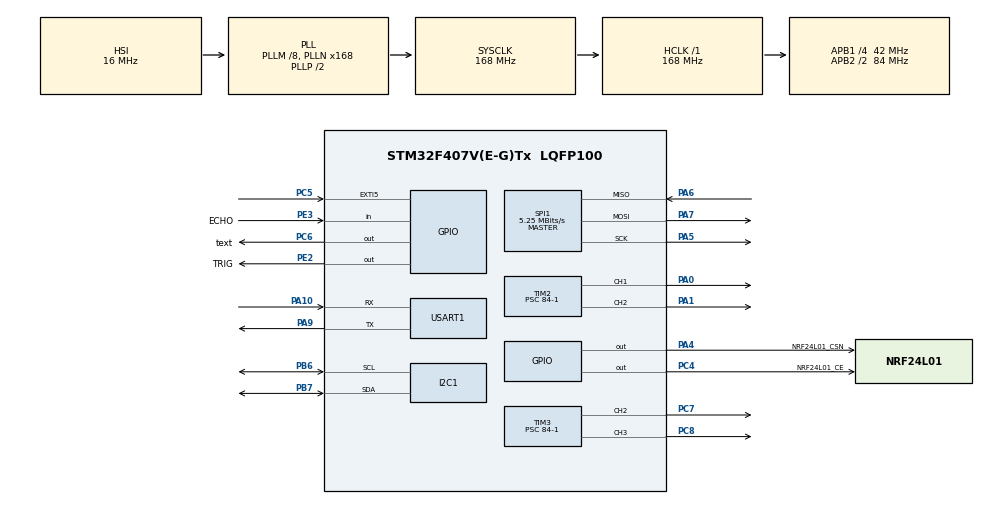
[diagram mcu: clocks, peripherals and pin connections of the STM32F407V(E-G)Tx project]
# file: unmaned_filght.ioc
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FREERTOS.Tasks01=defaultTask,24,128,StartDefaultTask,Default,NULL,Dynamic,NULL,NULL
I2C1.I2C_Mode=I2C_Fast
Mcu.Family=STM32F4
Mcu.Name=STM32F407V(E-G)Tx
Mcu.Package=LQFP100
NVIC.PriorityGroup=NVIC_PRIORITYGROUP_4
NVIC.TIM8_TRG_COM_TIM14_IRQn=true\:15\:0\:false\:false\:true\:false\:false\:true\:true
NVIC.TimeBase=TIM8_TRG_COM_TIM14_IRQn
NVIC.TimeBaseIP=TIM14
PA0-WKUP.Signal=S_TIM2_CH1_ETR
PA1.Signal=S_TIM2_CH2
PA10.Mode=Asynchronous
PA10.Signal=USART1_RX
PA13.Mode=Serial_Wire
PA13.Signal=SYS_JTMS-SWDIO
PA14.Mode=Serial_Wire
PA14.Signal=SYS_JTCK-SWCLK
PA4.GPIO_Label=NRF24L01_CSN
PA4.PinState=GPIO_PIN_SET
PA4.Signal=GPIO_Output
PA5.Mode=Full_Duplex_Master
PA5.Signal=SPI1_SCK
PA6.GPIO_PuPd=GPIO_PULLUP
PA6.Mode=Full_Duplex_Master
PA6.Signal=SPI1_MISO
PA7.Mode=Full_Duplex_Master
PA7.Signal=SPI1_MOSI
PA9.Mode=Asynchronous
PA9.Signal=USART1_TX
PB6.Mode=I2C
PB6.Signal=I2C1_SCL
PB7.Mode=I2C
PB7.Signal=I2C1_SDA
PC4.GPIO_Label=NRF24L01_CE
PC4.Signal=GPIO_Output
PC5.Signal=GPXTI5
PC6.GPIO_Label=text
PC6.Signal=GPIO_Output
PC7.Signal=S_TIM3_CH2
PC8.Signal=S_TIM3_CH3
PE2.GPIO_Label=TRIG
PE2.Signal=GPIO_Output
PE3.GPIO_Label=ECHO
PE3.Signal=GPIO_Input
PH0-OSC_IN.Mode=HSE-External-Oscillator
PH0-OSC_IN.Signal=RCC_OSC_IN
PH1-OSC_OUT.Mode=HSE-External-Oscillator
PH1-OSC_OUT.Signal=RCC_OSC_OUT
ProjectManager.HeapSize=0x200
ProjectManager.StackSize=0x400
ProjectManager.TargetToolchain=CMake
RCC.48MHZClocksFreq_Value=84000000
RCC.AHBFreq_Value=168000000
RCC.APB1CLKDivider=RCC_HCLK_DIV4
RCC.APB1Freq_Value=42000000
RCC.APB1TimFreq_Value=84000000
RCC.APB2CLKDivider=RCC_HCLK_DIV2
RCC.APB2Freq_Value=84000000
RCC.APB2TimFreq_Value=168000000
RCC.CortexFreq_Value=168000000
RCC.HCLKFreq_Value=168000000
RCC.HSE_VALUE=25000000
RCC.HSI_VALUE=16000000
RCC.LSE_VALUE=32768
RCC.PLLM=8
RCC.PLLN=168
RCC.SYSCLKFreq_VALUE=168000000
RCC.SYSCLKSource=RCC_SYSCLKSOURCE_PLLCLK
RCC.VCOOutputFreq_Value=336000000
SH.S_TIM2_CH1_ETR.0=TIM2_CH1,PWM Generation1 CH1
SH.S_TIM2_CH2.0=TIM2_CH2,PWM Generation2 CH2
SH.S_TIM3_CH2.0=TIM3_CH2,PWM Generation2 CH2
SH.S_TIM3_CH3.0=TIM3_CH3,PWM Generation3 CH3
SPI1.BaudRatePrescaler=SPI_BAUDRATEPRESCALER_16
SPI1.CalculateBaudRate=5.25 MBits/s
SPI1.Direction=SPI_DIRECTION_2LINES
SPI1.Mode=SPI_MODE_MASTER
SPI1.VirtualType=VM_MASTER
TIM2.Channel-PWM\ Generation1\ CH1=TIM_CHANNEL_1
TIM2.Channel-PWM\ Generation2\ CH2=TIM_CHANNEL_2
TIM2.Period=20000-1
TIM2.Prescaler=84-1
TIM2.Pulse-PWM\ Generation1\ CH1=1000
TIM2.Pulse-PWM\ Generation2\ CH2=1000
TIM3.Channel-PWM\ Generation2\ CH2=TIM_CHANNEL_2
TIM3.Channel-PWM\ Generation3\ CH3=TIM_CHANNEL_3
TIM3.Period=20000-1
TIM3.Prescaler=84-1
TIM3.Pulse-PWM\ Generation3\ CH3=1000
TIM4.Prescaler=84-1
USART1.VirtualMode=VM_ASYNC
VP_FREERTOS_VS_CMSIS_V2.Mode=CMSIS_V2
VP_SYS_VS_tim14.Mode=TIM14
VP_TIM2_VS_ClockSourceINT.Mode=Internal
VP_TIM3_VS_ClockSourceINT.Mode=Internal
VP_TIM4_VS_ClockSourceINT.Mode=Internal
board=custom

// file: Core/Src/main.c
/* USER CODE BEGIN Header */
/**
 ******************************************************************************
 * @file           : main.c
 * @brief          : Main program body
 ******************************************************************************
 * @attention
 *
 * Copyright (c) 2026 STMicroelectronics.
 * All rights reserved.
 *
 * This software is licensed under terms that can be found in the LICENSE file
 * in the root directory of this software component.
 * If no LICENSE file comes with this software, it is provided AS-IS.
 *
 ******************************************************************************
 */
/* USER CODE END Header */
#include "main.h"
#include "cmsis_os.h"
#include "i2c.h"
#include "spi.h"
#include "tim.h"
#include "usart.h"
#include "gpio.h"

/* USER CODE BEGIN Includes */
#include "freertos_start.h"
/* USER CODE END Includes */

void SystemClock_Config(void);
void MX_FREERTOS_Init(void);

int main(void)
{

  /* MCU Configuration--------------------------------------------------------*/

  /* Reset of all peripherals, Initializes the Flash interface and the Systick. */
  HAL_Init();

  /* Configure the system clock */
  SystemClock_Config();

  /* Initialize all configured peripherals */
  MX_GPIO_Init();
  MX_SPI1_Init();
  MX_USART1_UART_Init();
  MX_I2C1_Init();
  MX_TIM2_Init();
  MX_TIM3_Init();
  MX_TIM4_Init();
  /* USER CODE BEGIN 2 */
  Start_Rtos();
  /* USER CODE END 2 */

  /* Init scheduler */
  osKernelInitialize();  /* Call init function for freertos objects (in cmsis_os2.c) */
  MX_FREERTOS_Init();

  /* Start scheduler */
  osKernelStart();

  /* We should never get here as control is now taken by the scheduler */

  /* Infinite loop */
  while (1) {

  }
}

void SystemClock_Config(void)
{
  RCC_OscInitTypeDef RCC_OscInitStruct = {0};
  RCC_ClkInitTypeDef RCC_ClkInitStruct = {0};

  /** Configure the main internal regulator output voltage
  */
  __HAL_RCC_PWR_CLK_ENABLE();
  __HAL_PWR_VOLTAGESCALING_CONFIG(PWR_REGULATOR_VOLTAGE_SCALE1);

  /** Initializes the RCC Oscillators according to the specified parameters
  * in the RCC_OscInitTypeDef structure.
  */
  RCC_OscInitStruct.OscillatorType = RCC_OSCILLATORTYPE_HSI;
  RCC_OscInitStruct.HSIState = RCC_HSI_ON;
  RCC_OscInitStruct.HSICalibrationValue = RCC_HSICALIBRATION_DEFAULT;
  RCC_OscInitStruct.PLL.PLLState = RCC_PLL_ON;
  RCC_OscInitStruct.PLL.PLLSource = RCC_PLLSOURCE_HSI;
  RCC_OscInitStruct.PLL.PLLM = 8;
  RCC_OscInitStruct.PLL.PLLN = 168;
  RCC_OscInitStruct.PLL.PLLP = RCC_PLLP_DIV2;
  RCC_OscInitStruct.PLL.PLLQ = 4;
  if (HAL_RCC_OscConfig(&RCC_OscInitStruct) != HAL_OK)
  {
    Error_Handler();
  }

  /** Initializes the CPU, AHB and APB buses clocks
  */
  RCC_ClkInitStruct.ClockType = RCC_CLOCKTYPE_HCLK|RCC_CLOCKTYPE_SYSCLK
                              |RCC_CLOCKTYPE_PCLK1|RCC_CLOCKTYPE_PCLK2;
  RCC_ClkInitStruct.SYSCLKSource = RCC_SYSCLKSOURCE_PLLCLK;
  RCC_ClkInitStruct.AHBCLKDivider = RCC_SYSCLK_DIV1;
  RCC_ClkInitStruct.APB1CLKDivider = RCC_HCLK_DIV4;
  RCC_ClkInitStruct.APB2CLKDivider = RCC_HCLK_DIV2;

  if (HAL_RCC_ClockConfig(&RCC_ClkInitStruct, FLASH_LATENCY_5) != HAL_OK)
  {
    Error_Handler();
  }
}

void HAL_TIM_PeriodElapsedCallback(TIM_HandleTypeDef *htim)
{
  if (htim->Instance == TIM14)
  {
    HAL_IncTick();
  }
}

void Error_Handler(void)
{
  __disable_irq();
  while (1) {
  }
}
#ifdef USE_FULL_ASSERT
/**
  * @brief  Reports the name of the source file and the source line number
  *         where the assert_param error has occurred.
  * @param  file: pointer to the source file name
  * @param  line: assert_param error line source number
  * @retval None
  */
void assert_failed(uint8_t *file, uint32_t line)
{
  /* USER CODE BEGIN 6 */
  /* User can add his own implementation to report the file name and line
     number, ex: printf("Wrong parameters value: file %s on line %d\r\n", file,
     line) */
  /* USER CODE END 6 */
}
#endif /* USE_FULL_ASSERT */
